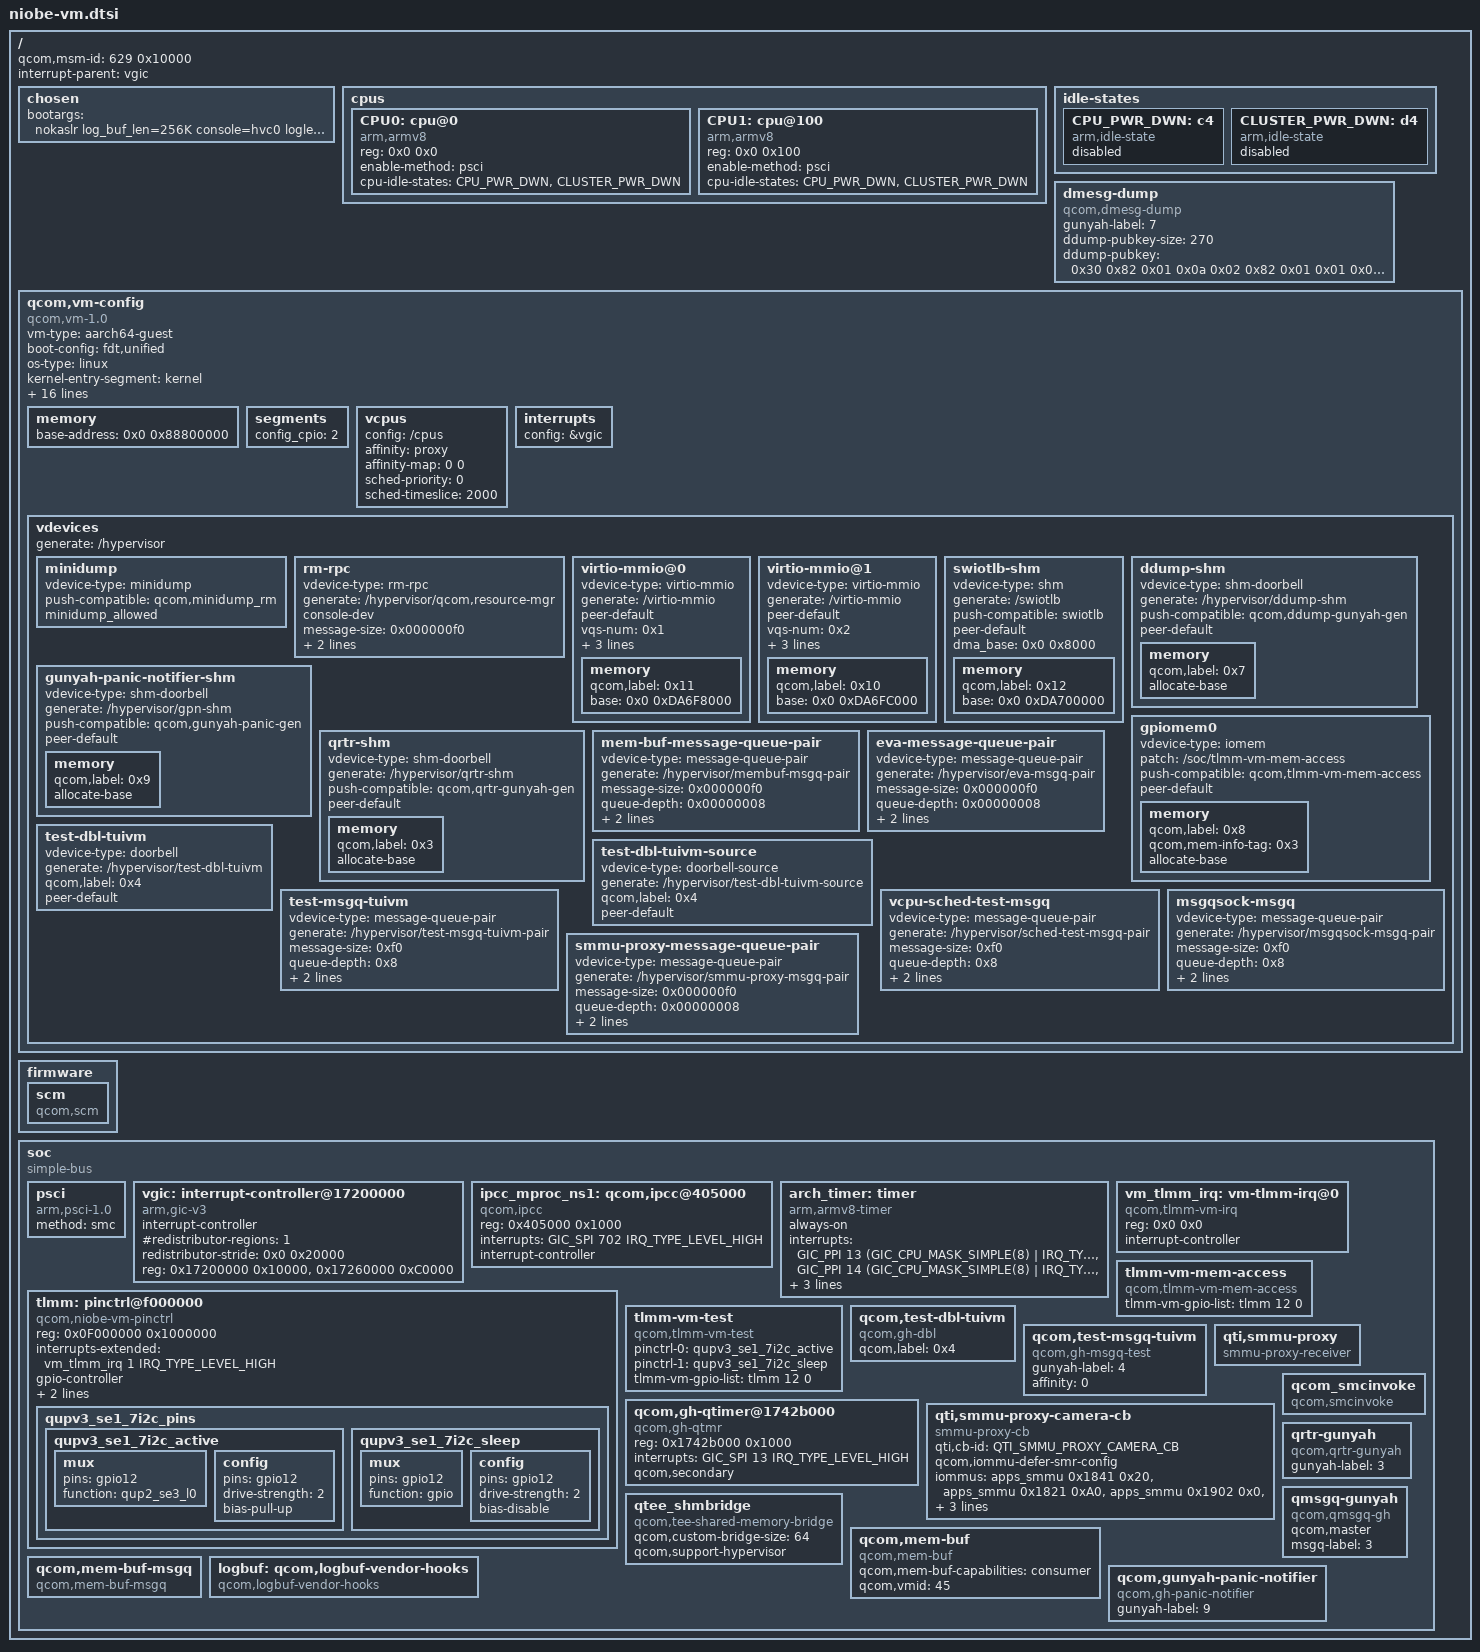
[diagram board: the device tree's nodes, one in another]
#include <dt-bindings/interrupt-controller/arm-gic.h>
#include <dt-bindings/clock/qcom,gcc-niobe.h>
#include <dt-bindings/arm/msm/qti-smmu-proxy-dt-ids.h>
#include <dt-bindings/soc/qcom,ipcc.h>

/ {
	#address-cells = <0x2>;
	#size-cells = <0x2>;
	qcom,msm-id = <629 0x10000>;
	interrupt-parent = <&vgic>;

	chosen {
		bootargs = "nokaslr log_buf_len=256K console=hvc0 loglevel=8";
	};

	cpus {
		#address-cells = <0x2>;
		#size-cells = <0x0>;

		CPU0: cpu@0 {
			compatible = "arm,armv8";
			reg = <0x0 0x0>;
			device_type = "cpu";
			enable-method = "psci";
			cpu-idle-states = <&CPU_PWR_DWN
					   &CLUSTER_PWR_DWN>;
		};

		CPU1: cpu@100 {
			compatible = "arm,armv8";
			reg = <0x0 0x100>;
			device_type = "cpu";
			enable-method = "psci";
			cpu-idle-states = <&CPU_PWR_DWN
					   &CLUSTER_PWR_DWN>;

		};
	};

	idle-states {
		CPU_PWR_DWN: c4 {  /* Using Gold C4 latencies */
			compatible = "arm,idle-state";
			status = "disabled";
		};

		CLUSTER_PWR_DWN: d4 { /* C4+D4 */
			compatible = "arm,idle-state";
			status = "disabled";
		};
	};

	dmesg-dump {
		compatible = "qcom,dmesg-dump";
		gunyah-label = <7>;
		ddump-pubkey-size = <270>;
		ddump-pubkey = /bits/ 8 <0x30 0x82 0x01 0x0a 0x02 0x82 0x01 0x01 0x00 0xe6 0x4b 0x31 0x82 0x61 0x14 0xf2
				0xbe 0xd1 0xe4 0xde 0xe7 0xed 0xba 0x8f 0x3b 0x23 0x5f 0x7a 0xb8 0x16 0x40 0x96
				0xae 0x77 0x5e 0x1b 0xf0 0x3f 0x39 0xab 0x69 0x90 0xb1 0xd4 0x70 0xcb 0x66 0xbc
				0x41 0x08 0x1d 0x37 0xdb 0x49 0xc8 0x49 0x5b 0x99 0x5c 0x32 0xbe 0x62 0xd5 0xa7
				0x3c 0x0f 0xa4 0x4b 0x43 0x49 0xdb 0x54 0x69 0x06 0x0c 0xe5 0x99 0xe5 0xf9 0x1e
				0x25 0x84 0x17 0x47 0x62 0x2b 0x5d 0x0d 0xec 0x5e 0xc6 0xb5 0x86 0xb9 0x75 0x6d
				0xfe 0x7d 0x35 0x4f 0x35 0xc1 0x48 0x10 0x75 0x4c 0x57 0x6b 0x46 0x4b 0xff 0x5b
				0x52 0x22 0x40 0x2c 0xb0 0x47 0xe1 0x47 0xc4 0xe5 0x47 0x0c 0x56 0xe8 0x17 0xd0
				0x7e 0xc3 0x4d 0x9f 0xea 0xd0 0xea 0x87 0xe5 0x51 0x39 0xe8 0x45 0x4c 0x54 0x27
				0x9c 0x50 0x38 0xb7 0x72 0x93 0x12 0x0b 0xa1 0x2f 0x9e 0x04 0x92 0x20 0x6e 0x31
				0x42 0x87 0xe1 0xfe 0x88 0x3f 0xe5 0x09 0xe1 0xf9 0xbe 0x44 0xc6 0xbf 0x10 0x79
				0x36 0x47 0x7b 0xa0 0x8e 0x27 0x31 0xa3 0x70 0x69 0x01 0x54 0x92 0xf4 0x42 0xbd
				0xcd 0x7e 0x79 0x2b 0x2c 0xe1 0xd4 0xba 0x6e 0x34 0xc6 0xe6 0xc6 0x5c 0x63 0xd0
				0x7f 0x39 0x1f 0xe8 0x8d 0x67 0xe6 0x27 0x67 0x0d 0x16 0x57 0x94 0xd1 0xfb 0xdf
				0xce 0xaf 0xfd 0x43 0xb3 0xbe 0x5d 0x83 0x4b 0x93 0x05 0xe8 0xdf 0x04 0xad 0xac
				0xeb 0xa6 0x81 0xa7 0xd5 0x04 0x63 0xbf 0x83 0xb8 0x0c 0xbc 0x20 0x18 0xb5 0x50
				0xd7 0x61 0x84 0x11 0xca 0x2d 0x22 0xb3 0x29 0x02 0x03 0x01 0x00 0x01>;
	};

	qcom,vm-config {
		compatible = "qcom,vm-1.0";
		vm-type = "aarch64-guest";
		boot-config = "fdt,unified";
		os-type = "linux";
		kernel-entry-segment = "kernel";
		kernel-entry-offset = <0x0 0x0>;
		vendor = "QTI";
		image-name = "qcom,trustedvm";
		qcom,pasid = <0x0 0x1c>;
		qcom,qtee-config-info = "p=3,9,39,77,78,7C,8F,97,C8,FE,11B,159,199,47E,7F1,CDF,10C;";
		qcom,secdomain-ids = <45>;
		qcom,primary-vm-index = <0>;
		vm-uri = "vmuid/trusted-ui";
		vm-guid = "598085da-c516-5b25-a9c1-927a02819770";
		qcom,sensitive;

		/* For LEVM pored usecases is SE4 and SE7, for SE4 we used gpii4
		 * and irq no is 315, for SE7 we used gpii5 and irq no is 316.
		 */
		gic-irq-ranges = <101 101
				  315 315
				  734 734
				  316 316>; /* PVM->SVM IRQ transfer */

		iomemory-ranges = <0x0 0x405000 0x0 0x405000 0x0 0x1000 0x0>;

		vm-attrs = "crash-fatal", "context-dump";

		memory {
			#address-cells = <0x2>;
			#size-cells = <0x0>;
			/*
			 * IPA address linux image is loaded at. Must be within
			 * first 1GB due to memory hotplug requirement.
			 */
			base-address = <0x0 0x88800000 >;
		};

		segments {
			config_cpio = <2>;
		};

		vcpus {
			config = "/cpus";
			affinity = "proxy";
			affinity-map = <0 0>;
			sched-priority = <0>;       /* relative to PVM */
			sched-timeslice = <2000>;   /* in ms */
		};

		interrupts {
			config = &vgic;
		};

		vdevices {
			generate = "/hypervisor";

			minidump {
				vdevice-type = "minidump";
				push-compatible = "qcom,minidump_rm";
				minidump_allowed;
			};

			rm-rpc {
				vdevice-type = "rm-rpc";
				generate = "/hypervisor/qcom,resource-mgr";
				console-dev;
				message-size = <0x000000f0>;
				queue-depth = <0x00000008>;
				qcom,label = <0x1>;
			};

			virtio-mmio@0 {
				vdevice-type = "virtio-mmio";
				generate = "/virtio-mmio";
				peer-default;
				vqs-num = <0x1>;
				push-compatible = "virtio,mmio";
				dma-coherent;
				dma_base = <0x0 0x0>;
				memory {
					qcom,label = <0x11>;			//for persist.img
					#address-cells = <0x2>;
					base = <0x0 0xDA6F8000>;
				};
			};

			virtio-mmio@1 {
				vdevice-type = "virtio-mmio";
				generate = "/virtio-mmio";
				peer-default;
				vqs-num = <0x2>;
				push-compatible = "virtio,mmio";
				dma-coherent;
				dma_base = <0x0 0x4000>;
				memory {
					qcom,label = <0x10>;			//for system.img
					#address-cells = <0x2>;
					base = <0x0 0xDA6FC000>;
				};
			};

			swiotlb-shm {
				vdevice-type = "shm";
				generate = "/swiotlb";
				push-compatible = "swiotlb";
				peer-default;
				dma_base = <0x0 0x8000>;
				memory {
					qcom,label = <0x12>;
					#address-cells = <0x2>;
					base = <0x0 0xDA700000>;
				};
			};

			ddump-shm {
				vdevice-type = "shm-doorbell";
				generate = "/hypervisor/ddump-shm";
				push-compatible = "qcom,ddump-gunyah-gen";
				peer-default;
				memory {
					qcom,label = <0x7>;
					allocate-base;
				};
			};

			gunyah-panic-notifier-shm {
				vdevice-type = "shm-doorbell";
				generate = "/hypervisor/gpn-shm";
				push-compatible = "qcom,gunyah-panic-gen";
				peer-default;
				memory {
					qcom,label = <0x9>;
					allocate-base;
				};
			};

			gpiomem0 {
				vdevice-type = "iomem";
				patch = "/soc/tlmm-vm-mem-access";
				push-compatible = "qcom,tlmm-vm-mem-access";
				peer-default;
				memory {
					qcom,label = <0x8>;
					qcom,mem-info-tag = <0x3>;
					allocate-base;
				};
			};

			qrtr-shm {
				vdevice-type = "shm-doorbell";
				generate = "/hypervisor/qrtr-shm";
				push-compatible = "qcom,qrtr-gunyah-gen";
				peer-default;
				memory {
					qcom,label = <0x3>;
					allocate-base;
				};
			};

			mem-buf-message-queue-pair {
				vdevice-type = "message-queue-pair";
				generate = "/hypervisor/membuf-msgq-pair";
				message-size = <0x000000f0>;
				queue-depth = <0x00000008>;
				peer-default;
				qcom,label = <0x0000001>;
			};

			eva-message-queue-pair {
				vdevice-type = "message-queue-pair";
				generate = "/hypervisor/eva-msgq-pair";
				message-size = <0x000000f0>;
				queue-depth = <0x00000008>;
				peer-default;
				qcom,label =<0x7>;
			};

			test-dbl-tuivm {
				vdevice-type = "doorbell";
				generate = "/hypervisor/test-dbl-tuivm";
				qcom,label = <0x4>;
				peer-default;
			};

			test-dbl-tuivm-source {
				vdevice-type = "doorbell-source";
				generate = "/hypervisor/test-dbl-tuivm-source";
				qcom,label = <0x4>;
				peer-default;
			};

			test-msgq-tuivm {
				vdevice-type = "message-queue-pair";
				generate = "/hypervisor/test-msgq-tuivm-pair";
				message-size = <0xf0>;
				queue-depth = <0x8>;
				qcom,label = <0x4>;
				peer-default;
			};

			vcpu-sched-test-msgq {
				vdevice-type = "message-queue-pair";
				generate = "/hypervisor/sched-test-msgq-pair";
				message-size = <0xf0>;
				queue-depth = <0x8>;
				qcom,label = <0x8>;
				peer-default;
			};

			smmu-proxy-message-queue-pair {
				vdevice-type = "message-queue-pair";
				generate = "/hypervisor/smmu-proxy-msgq-pair";
				message-size = <0x000000f0>;
				queue-depth = <0x00000008>;
				peer-default;
				qcom,label = <0xA>;
			};

			msgqsock-msgq {
				vdevice-type = "message-queue-pair";
				generate = "/hypervisor/msgqsock-msgq-pair";
				message-size = <0xf0>;
				queue-depth = <0x8>;
				peer = "vm-name:qcom,oemvm";
				qcom,label = <0x3>;
			};

		};
	};

	firmware: firmware {
		scm {
			compatible = "qcom,scm";
		};
	};

	soc: soc { };
};

&soc {
	#address-cells = <1>;
	#size-cells = <1>;
	ranges = <0 0 0 0xffffffff>;
	compatible = "simple-bus";

	psci {
		compatible = "arm,psci-1.0";
		method = "smc";
	};

	vgic: interrupt-controller@17200000 {
		compatible = "arm,gic-v3";
		interrupt-controller;
		#interrupt-cells = <0x3>;
		#redistributor-regions = <1>;
		redistributor-stride = <0x0 0x20000>;
		reg = <0x17200000 0x10000>,     /* GICD */
		      <0x17260000 0xC0000>;    /* GICR * 8 */
	};

	ipcc_mproc_ns1: qcom,ipcc@405000 {
		compatible = "qcom,ipcc";
		reg = <0x405000 0x1000>;
		interrupts = <GIC_SPI 702 IRQ_TYPE_LEVEL_HIGH>;
		interrupt-controller;
		#interrupt-cells = <3>;
		#mbox-cells = <2>;
	};

	arch_timer: timer {
		compatible = "arm,armv8-timer";
		always-on;
		interrupts = <GIC_PPI 13 (GIC_CPU_MASK_SIMPLE(8) | IRQ_TYPE_LEVEL_LOW)>,
			     <GIC_PPI 14 (GIC_CPU_MASK_SIMPLE(8) | IRQ_TYPE_LEVEL_LOW)>,
			     <GIC_PPI 11 (GIC_CPU_MASK_SIMPLE(8) | IRQ_TYPE_LEVEL_LOW)>,
			     <GIC_PPI 12 (GIC_CPU_MASK_SIMPLE(8) | IRQ_TYPE_LEVEL_LOW)>;
		clock-frequency = <19200000>;
	};

	vm_tlmm_irq: vm-tlmm-irq@0 {
		compatible = "qcom,tlmm-vm-irq";
		reg = <0x0 0x0>;
		interrupt-controller;
		#interrupt-cells = <2>;
	};

	tlmm: pinctrl@f000000 {
		compatible = "qcom,niobe-vm-pinctrl";
		reg = <0x0F000000 0x1000000>;
		interrupts-extended = <&vm_tlmm_irq 1 IRQ_TYPE_LEVEL_HIGH>;
		gpio-controller;
		#gpio-cells = <2>;
		interrupt-controller;
		#interrupt-cells = <2>;
		/* Valid pins */
		gpios = /bits/ 16 <12>;
	};

	tlmm-vm-mem-access {
		compatible = "qcom,tlmm-vm-mem-access";
		tlmm-vm-gpio-list = <&tlmm 12 0>;
	};

	tlmm-vm-test {
		compatible = "qcom,tlmm-vm-test";
		pinctrl-names = "active", "sleep";
		pinctrl-0 = <&qupv3_se1_7i2c_active>;
		pinctrl-1 = <&qupv3_se1_7i2c_sleep>;
		tlmm-vm-gpio-list = <&tlmm 12 0>;
	};

	pinctrl@f000000 {
		qupv3_se1_7i2c_pins: qupv3_se1_7i2c_pins {
			qupv3_se1_7i2c_active: qupv3_se1_7i2c_active {
				mux {
					pins = "gpio12";
					function = "qup2_se3_l0";
				};

				config {
					pins = "gpio12";
					drive-strength = <2>;
					bias-pull-up;
				};
			};

			qupv3_se1_7i2c_sleep: qupv3_se1_7i2c_sleep {
				mux {
					pins = "gpio12";
					function = "gpio";
				};

				config {
					pins = "gpio12";
					drive-strength = <2>;
					bias-disable;
				};
			};
		};
	};

	qcom,test-dbl-tuivm {
		compatible = "qcom,gh-dbl";
		qcom,label = <0x4>;
	};

	qcom,test-msgq-tuivm {
		compatible = "qcom,gh-msgq-test";
		gunyah-label = <4>;
		affinity = <0>;
	};

	qcom,gh-qtimer@1742b000 {
		compatible = "qcom,gh-qtmr";
		reg = <0x1742b000 0x1000>;
		reg-names = "qtmr-base";
		interrupts = <GIC_SPI 13 IRQ_TYPE_LEVEL_HIGH>;
		interrupt-names = "qcom,qtmr-intr";
		qcom,secondary;
	};

	qti,smmu-proxy {
		compatible = "smmu-proxy-receiver";
	};

	qti,smmu-proxy-camera-cb {
		compatible = "smmu-proxy-cb";
		qti,cb-id = <QTI_SMMU_PROXY_CAMERA_CB>;
		qcom,iommu-defer-smr-config;
		iommus = <&apps_smmu 0x1841 0x20>,
			 <&apps_smmu 0x1821 0xA0>,
			 <&apps_smmu 0x1902 0x0>,
			 <&apps_smmu 0x1921 0x0>,
			 <&apps_smmu 0x0801 0x0>,
			 <&apps_smmu 0x19A7 0x0>;
		dma-coherent;
	};

	qcom_smcinvoke {
		compatible = "qcom,smcinvoke";
	};

	qtee_shmbridge {
		compatible = "qcom,tee-shared-memory-bridge";
		qcom,custom-bridge-size = <64>;
		qcom,support-hypervisor;
	};

	qrtr-gunyah {
		compatible = "qcom,qrtr-gunyah";
		gunyah-label = <3>;
	};

	qmsgq-gunyah {
		compatible = "qcom,qmsgq-gh";
		qcom,master;
		msgq-label = <3>;
	};

	qcom,mem-buf {
		compatible = "qcom,mem-buf";
		qcom,mem-buf-capabilities = "consumer";
		qcom,vmid = <45>;
	};

	qcom,mem-buf-msgq {
		compatible = "qcom,mem-buf-msgq";
	};

	logbuf: qcom,logbuf-vendor-hooks {
		compatible = "qcom,logbuf-vendor-hooks";
	};

	qcom,gunyah-panic-notifier {
		compatible = "qcom,gh-panic-notifier";
		gunyah-label = <9>;
	};
};

#include "niobe-vm-dma-heaps.dtsi"
#include "msm-arm-smmu-niobe-vm.dtsi"
